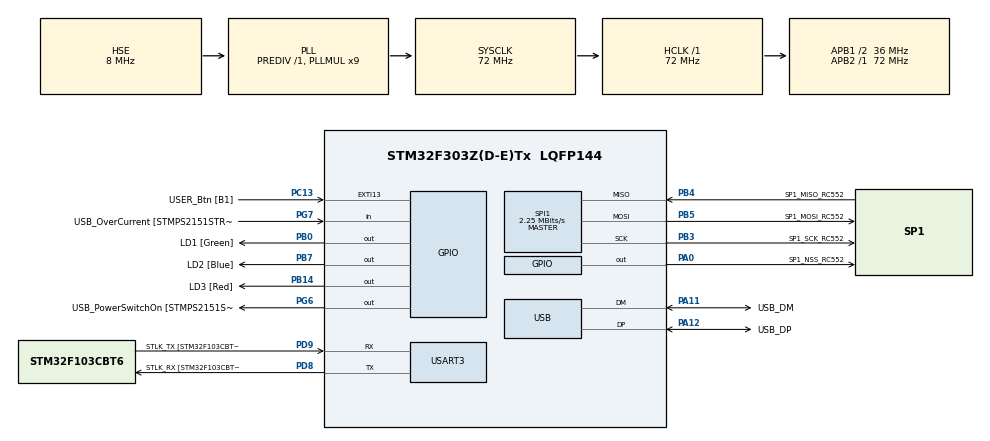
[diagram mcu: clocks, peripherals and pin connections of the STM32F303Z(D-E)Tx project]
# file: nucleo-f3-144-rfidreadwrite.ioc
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Mcu.Family=STM32F3
Mcu.Name=STM32F303Z(D-E)Tx
Mcu.Package=LQFP144
NVIC.PriorityGroup=NVIC_PRIORITYGROUP_4
NVIC.USB_LP_IRQn=true\:0\:0\:false\:false\:true\:false\:true\:true
PA0.GPIO_Label=SP1_NSS_RC552
PA0.Signal=GPIO_Output
PA11.GPIO_Label=USB_DM
PA11.Mode=Device
PA11.Signal=USB_DM
PA12.GPIO_Label=USB_DP
PA12.Mode=Device
PA12.Signal=USB_DP
PA13.GPIO_Label=TMS
PA13.Signal=SYS_JTMS-SWDIO
PA14.GPIO_Label=TCK
PA14.Signal=SYS_JTCK-SWCLK
PB0.GPIO_Label=LD1 [Green]
PB0.Signal=GPIO_Output
PB14.GPIO_Label=LD3 [Red]
PB14.Signal=GPIO_Output
PB3.GPIO_Label=SP1_SCK_RC552
PB3.Mode=Full_Duplex_Master
PB3.Signal=SPI1_SCK
PB4.GPIO_Label=SP1_MISO_RC552
PB4.Mode=Full_Duplex_Master
PB4.Signal=SPI1_MISO
PB5.GPIO_Label=SP1_MOSI_RC552
PB5.Mode=Full_Duplex_Master
PB5.Signal=SPI1_MOSI
PB7.GPIO_Label=LD2 [Blue]
PB7.Signal=GPIO_Output
PC13.GPIO_Label=USER_Btn [B1]
PC13.Signal=GPXTI13
PC14-OSC32_IN.Mode=LSE-External-Oscillator
PC14-OSC32_IN.Signal=RCC_OSC32_IN
PC15-OSC32_OUT.Mode=LSE-External-Oscillator
PC15-OSC32_OUT.Signal=RCC_OSC32_OUT
PD8.GPIO_Label=STLK_RX [STM32F103CBT6_PA3]
PD8.Mode=Asynchronous
PD8.Signal=USART3_TX
PD9.GPIO_Label=STLK_TX [STM32F103CBT6_PA2]
PD9.Mode=Asynchronous
PD9.Signal=USART3_RX
PF0-OSC_IN.GPIO_Label=MCO [STM32F103CBT6_PA8]
PF0-OSC_IN.Mode=HSE-External-Clock-Source
PF0-OSC_IN.Signal=RCC_OSC_IN
PG6.GPIO_Label=USB_PowerSwitchOn [STMPS2151STR_EN]
PG6.Signal=GPIO_Output
PG7.GPIO_Label=USB_OverCurrent [STMPS2151STR_FAULT]
PG7.Signal=GPIO_Input
ProjectManager.HeapSize=0x200
ProjectManager.StackSize=0x400
ProjectManager.TargetToolchain=STM32CubeIDE
RCC.AHBFreq_Value=72000000
RCC.APB1CLKDivider=RCC_HCLK_DIV2
RCC.APB1Freq_Value=36000000
RCC.APB1TimFreq_Value=72000000
RCC.APB2Freq_Value=72000000
RCC.APB2TimFreq_Value=72000000
RCC.CortexFreq_Value=72000000
RCC.HCLKFreq_Value=72000000
RCC.HSE_VALUE=8000000
RCC.HSI_VALUE=8000000
RCC.PLLMUL=RCC_PLL_MUL9
RCC.PRESCALERUSB=RCC_USBCLKSOURCE_PLL_DIV1_5
RCC.SYSCLKFreq_VALUE=72000000
RCC.SYSCLKSourceVirtual=RCC_SYSCLKSOURCE_PLLCLK
RCC.USBFreq_Value=48000000
SPI1.BaudRatePrescaler=SPI_BAUDRATEPRESCALER_32
SPI1.CalculateBaudRate=2.25 MBits/s
SPI1.DataSize=SPI_DATASIZE_8BIT
SPI1.Direction=SPI_DIRECTION_2LINES
SPI1.Mode=SPI_MODE_MASTER
SPI1.VirtualType=VM_MASTER
USART3.VirtualMode-Asynchronous=VM_ASYNC
USB_DEVICE.CLASS_NAME_FS=CDC
USB_DEVICE.VirtualMode=Cdc
USB_DEVICE.VirtualModeFS=Cdc_FS
VP_RTC_VS_RTC_Activate.Mode=RTC_Enabled
VP_USB_DEVICE_VS_USB_DEVICE_CDC_FS.Mode=CDC_FS
board=NUCLEO-F303ZE

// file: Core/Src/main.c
/* USER CODE BEGIN Header */
/**
  ******************************************************************************
  * @file           : main.c
  * @brief          : Main program body
  ******************************************************************************
  * @attention
  *
  * Copyright (c) 2023 STMicroelectronics.
  * All rights reserved.
  *
  * This software is licensed under terms that can be found in the LICENSE file
  * in the root directory of this software component.
  * If no LICENSE file comes with this software, it is provided AS-IS.
  *
  ******************************************************************************
  */
/* USER CODE END Header */
#include "main.h"
#include "usb_device.h"

/* USER CODE BEGIN Includes */
#include "usbd_cdc_if.h"
#include "RC522.h"
/* USER CODE END Includes */

/* USER CODE BEGIN PM */
#define VirCOMPrint(buf, len) CDC_Transmit_FS(buf, len)
/* USER CODE END PM */

RTC_HandleTypeDef hrtc;

SPI_HandleTypeDef hspi1;

UART_HandleTypeDef huart3;

void SystemClock_Config(void);
static void MX_GPIO_Init(void);
static void MX_RTC_Init(void);
static void MX_USART3_UART_Init(void);
static void MX_SPI1_Init(void);

int main(void)
{

  /* MCU Configuration--------------------------------------------------------*/

  /* Reset of all peripherals, Initializes the Flash interface and the Systick. */
  HAL_Init();

  /* Configure the system clock */
  SystemClock_Config();

  /* Initialize all configured peripherals */
  MX_GPIO_Init();
  MX_RTC_Init();
  MX_USART3_UART_Init();
  MX_SPI1_Init();
  MX_USB_DEVICE_Init();
  /* USER CODE BEGIN 2 */
  HAL_GPIO_TogglePin(GPIOG, GPIO_PIN_6); // Turns on Micro USB Port CN13 for Data Transmission
  	  	  	  	  	  	  	  	  	  	 // Unique step for usage of STM32F303ZE Nucleo Board USB Virtual COMPORT
  	  	  	  	  	  	  	  	  	     // as stated on p.24 Sec.6.9 in UM1974 User manual
  char txtBuf[8];						 // outputed to COMPORT

  /* USER CODE END 2 */

  /* Infinite loop */
  /* USER CODE BEGIN WHILE */
  while (1)
  {

	  HAL_Delay(100);
    /* USER CODE END WHILE */

  }
}

void SystemClock_Config(void)
{
  RCC_OscInitTypeDef RCC_OscInitStruct = {0};
  RCC_ClkInitTypeDef RCC_ClkInitStruct = {0};
  RCC_PeriphCLKInitTypeDef PeriphClkInit = {0};

  /** Initializes the RCC Oscillators according to the specified parameters
  * in the RCC_OscInitTypeDef structure.
  */
  RCC_OscInitStruct.OscillatorType = RCC_OSCILLATORTYPE_LSI|RCC_OSCILLATORTYPE_HSE;
  RCC_OscInitStruct.HSEState = RCC_HSE_BYPASS;
  RCC_OscInitStruct.HSIState = RCC_HSI_ON;
  RCC_OscInitStruct.LSIState = RCC_LSI_ON;
  RCC_OscInitStruct.PLL.PLLState = RCC_PLL_ON;
  RCC_OscInitStruct.PLL.PLLSource = RCC_PLLSOURCE_HSE;
  RCC_OscInitStruct.PLL.PLLMUL = RCC_PLL_MUL9;
  RCC_OscInitStruct.PLL.PREDIV = RCC_PREDIV_DIV1;
  if (HAL_RCC_OscConfig(&RCC_OscInitStruct) != HAL_OK)
  {
    Error_Handler();
  }

  /** Initializes the CPU, AHB and APB buses clocks
  */
  RCC_ClkInitStruct.ClockType = RCC_CLOCKTYPE_HCLK|RCC_CLOCKTYPE_SYSCLK
                              |RCC_CLOCKTYPE_PCLK1|RCC_CLOCKTYPE_PCLK2;
  RCC_ClkInitStruct.SYSCLKSource = RCC_SYSCLKSOURCE_PLLCLK;
  RCC_ClkInitStruct.AHBCLKDivider = RCC_SYSCLK_DIV1;
  RCC_ClkInitStruct.APB1CLKDivider = RCC_HCLK_DIV2;
  RCC_ClkInitStruct.APB2CLKDivider = RCC_HCLK_DIV1;

  if (HAL_RCC_ClockConfig(&RCC_ClkInitStruct, FLASH_LATENCY_2) != HAL_OK)
  {
    Error_Handler();
  }
  PeriphClkInit.PeriphClockSelection = RCC_PERIPHCLK_USB|RCC_PERIPHCLK_USART3
                              |RCC_PERIPHCLK_RTC;
  PeriphClkInit.Usart3ClockSelection = RCC_USART3CLKSOURCE_PCLK1;
  PeriphClkInit.RTCClockSelection = RCC_RTCCLKSOURCE_LSI;
  PeriphClkInit.USBClockSelection = RCC_USBCLKSOURCE_PLL_DIV1_5;
  if (HAL_RCCEx_PeriphCLKConfig(&PeriphClkInit) != HAL_OK)
  {
    Error_Handler();
  }
}

static void MX_RTC_Init(void)
{

  /** Initialize RTC Only
  */
  hrtc.Instance = RTC;
  hrtc.Init.HourFormat = RTC_HOURFORMAT_24;
  hrtc.Init.AsynchPrediv = 127;
  hrtc.Init.SynchPrediv = 255;
  hrtc.Init.OutPut = RTC_OUTPUT_DISABLE;
  hrtc.Init.OutPutPolarity = RTC_OUTPUT_POLARITY_HIGH;
  hrtc.Init.OutPutType = RTC_OUTPUT_TYPE_OPENDRAIN;
  if (HAL_RTC_Init(&hrtc) != HAL_OK)
  {
    Error_Handler();
  }

}

static void MX_SPI1_Init(void)
{

  /* SPI1 parameter configuration*/
  hspi1.Instance = SPI1;
  hspi1.Init.Mode = SPI_MODE_MASTER;
  hspi1.Init.Direction = SPI_DIRECTION_2LINES;
  hspi1.Init.DataSize = SPI_DATASIZE_8BIT;
  hspi1.Init.CLKPolarity = SPI_POLARITY_LOW;
  hspi1.Init.CLKPhase = SPI_PHASE_1EDGE;
  hspi1.Init.NSS = SPI_NSS_SOFT;
  hspi1.Init.BaudRatePrescaler = SPI_BAUDRATEPRESCALER_32;
  hspi1.Init.FirstBit = SPI_FIRSTBIT_MSB;
  hspi1.Init.TIMode = SPI_TIMODE_DISABLE;
  hspi1.Init.CRCCalculation = SPI_CRCCALCULATION_DISABLE;
  hspi1.Init.CRCPolynomial = 7;
  hspi1.Init.CRCLength = SPI_CRC_LENGTH_DATASIZE;
  hspi1.Init.NSSPMode = SPI_NSS_PULSE_ENABLE;
  if (HAL_SPI_Init(&hspi1) != HAL_OK)
  {
    Error_Handler();
  }

}

static void MX_USART3_UART_Init(void)
{

  huart3.Instance = USART3;
  huart3.Init.BaudRate = 38400;
  huart3.Init.WordLength = UART_WORDLENGTH_8B;
  huart3.Init.StopBits = UART_STOPBITS_1;
  huart3.Init.Parity = UART_PARITY_NONE;
  huart3.Init.Mode = UART_MODE_TX_RX;
  huart3.Init.HwFlowCtl = UART_HWCONTROL_NONE;
  huart3.Init.OverSampling = UART_OVERSAMPLING_16;
  huart3.Init.OneBitSampling = UART_ONE_BIT_SAMPLE_DISABLE;
  huart3.AdvancedInit.AdvFeatureInit = UART_ADVFEATURE_NO_INIT;
  if (HAL_UART_Init(&huart3) != HAL_OK)
  {
    Error_Handler();
  }

}

static void MX_GPIO_Init(void)
{
  GPIO_InitTypeDef GPIO_InitStruct = {0};

  /* GPIO Ports Clock Enable */
  __HAL_RCC_GPIOC_CLK_ENABLE();
  __HAL_RCC_GPIOF_CLK_ENABLE();
  __HAL_RCC_GPIOA_CLK_ENABLE();
  __HAL_RCC_GPIOB_CLK_ENABLE();
  __HAL_RCC_GPIOD_CLK_ENABLE();
  __HAL_RCC_GPIOG_CLK_ENABLE();

  /*Configure GPIO pin Output Level */
  HAL_GPIO_WritePin(SP1_NSS_RC552_GPIO_Port, SP1_NSS_RC552_Pin, GPIO_PIN_RESET);

  /*Configure GPIO pin Output Level */
  HAL_GPIO_WritePin(GPIOB, LD1_Pin|LD3_Pin|LD2_Pin, GPIO_PIN_RESET);

  /*Configure GPIO pin Output Level */
  HAL_GPIO_WritePin(USB_PowerSwitchOn_GPIO_Port, USB_PowerSwitchOn_Pin, GPIO_PIN_RESET);

  /*Configure GPIO pin : USER_Btn_Pin */
  GPIO_InitStruct.Pin = USER_Btn_Pin;
  GPIO_InitStruct.Mode = GPIO_MODE_IT_RISING;
  GPIO_InitStruct.Pull = GPIO_NOPULL;
  HAL_GPIO_Init(USER_Btn_GPIO_Port, &GPIO_InitStruct);

  /*Configure GPIO pin : SP1_NSS_RC552_Pin */
  GPIO_InitStruct.Pin = SP1_NSS_RC552_Pin;
  GPIO_InitStruct.Mode = GPIO_MODE_OUTPUT_PP;
  GPIO_InitStruct.Pull = GPIO_NOPULL;
  GPIO_InitStruct.Speed = GPIO_SPEED_FREQ_LOW;
  HAL_GPIO_Init(SP1_NSS_RC552_GPIO_Port, &GPIO_InitStruct);

  /*Configure GPIO pins : LD1_Pin LD3_Pin LD2_Pin */
  GPIO_InitStruct.Pin = LD1_Pin|LD3_Pin|LD2_Pin;
  GPIO_InitStruct.Mode = GPIO_MODE_OUTPUT_PP;
  GPIO_InitStruct.Pull = GPIO_NOPULL;
  GPIO_InitStruct.Speed = GPIO_SPEED_FREQ_LOW;
  HAL_GPIO_Init(GPIOB, &GPIO_InitStruct);

  /*Configure GPIO pin : USB_PowerSwitchOn_Pin */
  GPIO_InitStruct.Pin = USB_PowerSwitchOn_Pin;
  GPIO_InitStruct.Mode = GPIO_MODE_OUTPUT_PP;
  GPIO_InitStruct.Pull = GPIO_NOPULL;
  GPIO_InitStruct.Speed = GPIO_SPEED_FREQ_LOW;
  HAL_GPIO_Init(USB_PowerSwitchOn_GPIO_Port, &GPIO_InitStruct);

  /*Configure GPIO pin : USB_OverCurrent_Pin */
  GPIO_InitStruct.Pin = USB_OverCurrent_Pin;
  GPIO_InitStruct.Mode = GPIO_MODE_INPUT;
  GPIO_InitStruct.Pull = GPIO_NOPULL;
  HAL_GPIO_Init(USB_OverCurrent_GPIO_Port, &GPIO_InitStruct);

}

void Error_Handler(void)
{
  __disable_irq();
  while (1)
  {
  }
}
